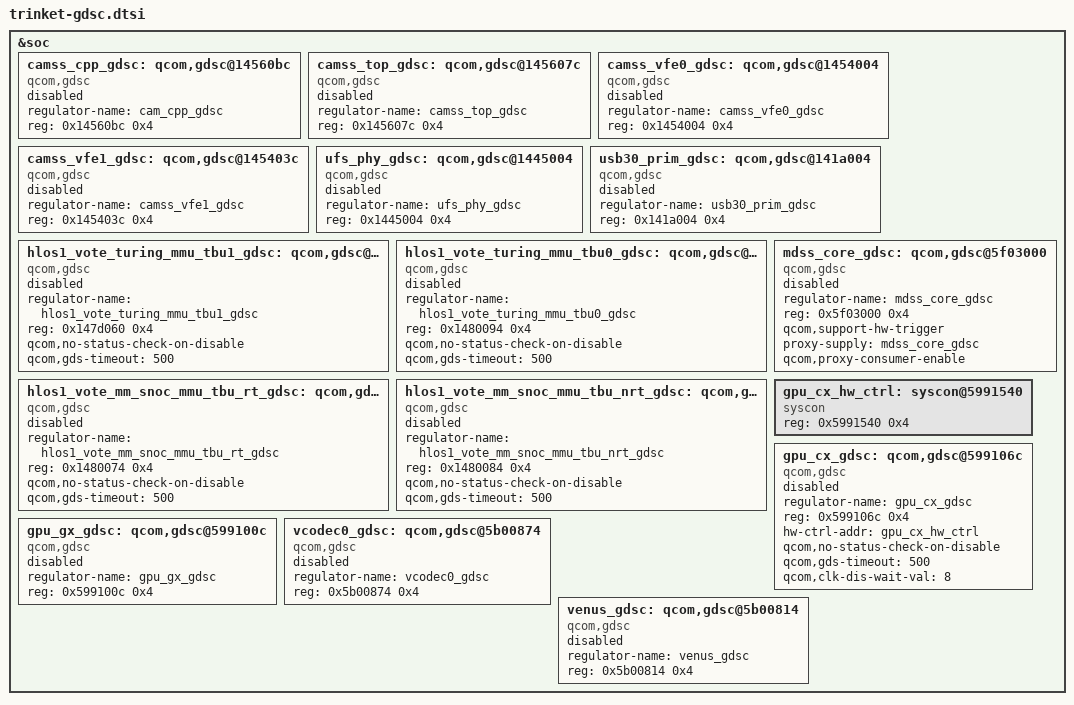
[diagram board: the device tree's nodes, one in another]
/*
 * Copyright (c) 2018, The Linux Foundation. All rights reserved.
 *
 * This program is free software; you can redistribute it and/or modify
 * it under the terms of the GNU General Public License version 2 and
 * only version 2 as published by the Free Software Foundation.
 *
 * This program is distributed in the hope that it will be useful,
 * but WITHOUT ANY WARRANTY; without even the implied warranty of
 * MERCHANTABILITY or FITNESS FOR A PARTICULAR PURPOSE.  See the
 * GNU General Public License for more details.
 */

&soc {
	/* GDSCs in Global CC */
	camss_cpp_gdsc: qcom,gdsc@14560bc {
		compatible = "qcom,gdsc";
		regulator-name = "cam_cpp_gdsc";
		reg = <0x14560bc 0x4>;
		status = "disabled";
	};

	camss_top_gdsc: qcom,gdsc@145607c {
		compatible = "qcom,gdsc";
		regulator-name = "camss_top_gdsc";
		reg = <0x145607c 0x4>;
		status = "disabled";
	};

	camss_vfe0_gdsc: qcom,gdsc@1454004 {
		compatible = "qcom,gdsc";
		regulator-name = "camss_vfe0_gdsc";
		reg = <0x1454004 0x4>;
		status = "disabled";
	};

	camss_vfe1_gdsc: qcom,gdsc@145403c {
		compatible = "qcom,gdsc";
		regulator-name = "camss_vfe1_gdsc";
		reg = <0x145403c 0x4>;
		status = "disabled";
	};

	ufs_phy_gdsc: qcom,gdsc@1445004 {
		compatible = "qcom,gdsc";
		regulator-name = "ufs_phy_gdsc";
		reg = <0x1445004 0x4>;
		status = "disabled";
	};

	usb30_prim_gdsc: qcom,gdsc@141a004 {
		compatible = "qcom,gdsc";
		regulator-name = "usb30_prim_gdsc";
		reg = <0x141a004 0x4>;
		status = "disabled";
	};

	hlos1_vote_turing_mmu_tbu1_gdsc: qcom,gdsc@147d060 {
		compatible = "qcom,gdsc";
		regulator-name = "hlos1_vote_turing_mmu_tbu1_gdsc";
		reg = <0x147d060 0x4>;
		qcom,no-status-check-on-disable;
		qcom,gds-timeout = <500>;
		status = "disabled";
	};

	hlos1_vote_turing_mmu_tbu0_gdsc: qcom,gdsc@1480094 {
		compatible = "qcom,gdsc";
		regulator-name = "hlos1_vote_turing_mmu_tbu0_gdsc";
		reg = <0x1480094 0x4>;
		qcom,no-status-check-on-disable;
		qcom,gds-timeout = <500>;
		status = "disabled";
	};

	hlos1_vote_mm_snoc_mmu_tbu_rt_gdsc: qcom,gdsc@1480074 {
		compatible = "qcom,gdsc";
		regulator-name = "hlos1_vote_mm_snoc_mmu_tbu_rt_gdsc";
		reg = <0x1480074 0x4>;
		qcom,no-status-check-on-disable;
		qcom,gds-timeout = <500>;
		status = "disabled";
	};

	hlos1_vote_mm_snoc_mmu_tbu_nrt_gdsc: qcom,gdsc@1480084 {
		compatible = "qcom,gdsc";
		regulator-name = "hlos1_vote_mm_snoc_mmu_tbu_nrt_gdsc";
		reg = <0x1480084 0x4>;
		qcom,no-status-check-on-disable;
		qcom,gds-timeout = <500>;
		status = "disabled";
	};

	/* GDSCs in Display CC */
	mdss_core_gdsc: qcom,gdsc@5f03000 {
		compatible = "qcom,gdsc";
		regulator-name = "mdss_core_gdsc";
		reg = <0x5f03000 0x4>;
		qcom,support-hw-trigger;
		status = "disabled";
		proxy-supply = <&mdss_core_gdsc>;
		qcom,proxy-consumer-enable;
	};

	/* GDSCs in Graphics CC */
	gpu_cx_hw_ctrl: syscon@5991540 {
		compatible = "syscon";
		reg = <0x5991540 0x4>;
	};

	gpu_cx_gdsc: qcom,gdsc@599106c {
		compatible = "qcom,gdsc";
		regulator-name = "gpu_cx_gdsc";
		reg = <0x599106c 0x4>;
		hw-ctrl-addr = <&gpu_cx_hw_ctrl>;
		qcom,no-status-check-on-disable;
		qcom,gds-timeout = <500>;
		qcom,clk-dis-wait-val = <8>;
		status = "disabled";
	};

	gpu_gx_gdsc: qcom,gdsc@599100c {
		compatible = "qcom,gdsc";
		regulator-name = "gpu_gx_gdsc";
		reg = <0x599100c 0x4>;
		status = "disabled";
	};

	/* GDSCs in Video CC */
	vcodec0_gdsc: qcom,gdsc@5b00874 {
		compatible = "qcom,gdsc";
		regulator-name = "vcodec0_gdsc";
		reg = <0x5b00874 0x4>;
		status = "disabled";
	};

	venus_gdsc: qcom,gdsc@5b00814 {
		compatible = "qcom,gdsc";
		regulator-name = "venus_gdsc";
		reg = <0x5b00814 0x4>;
		status = "disabled";
	};
};
